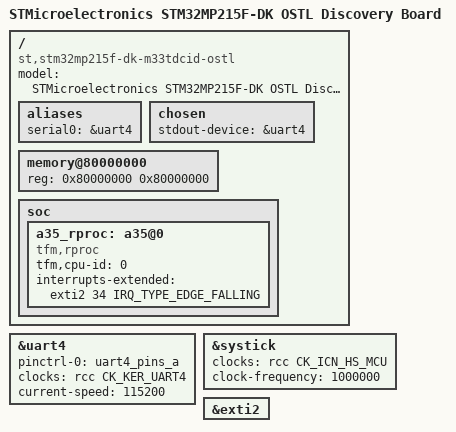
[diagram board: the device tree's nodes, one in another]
// SPDX-License-Identifier: (GPL-2.0-only OR BSD-3-Clause)
/*
 * Copyright (C) STMicroelectronics 2023 - All Rights Reserved
 */

/dts-v1/;

#include <dt-bindings/clock/stm32mp21-clksrc.h>
#include <dt-bindings/reset/st,stm32mp21-rcc.h>

#include "stm32mp215.dtsi"
#include "stm32mp21x-ns.dtsi"
#include "stm32mp215f-dk-cm33tdcid-ostl-resmem.dtsi"
#include "stm32mp215f-dk-cm33tdcid-ostl-ns-rcc.dtsi"
#include "stm32mp21-pinctrl.dtsi"
#include "stm32mp21xxan-pinctrl.dtsi"

/delete-node/ &a35_rproc;

/ {
	model = "STMicroelectronics STM32MP215F-DK OSTL Discovery Board";
	compatible = "st,stm32mp215f-dk-m33tdcid-ostl", "st,stm32mp215f-dk", "st,stm32mp215";

	aliases {
		serial0 = &uart4;
	};

	chosen {
		stdout-device = &uart4;
	};

	memory@80000000 {
		device_type = "memory";
		reg = <0x80000000 0x80000000>;
	};

	soc {
		a35_rproc: a35@0 {
			compatible = "tfm,rproc";
			#remoteproc-cells = <0>;
			tfm,cpu-id = <0>;
			interrupts-extended = <&exti2 34 IRQ_TYPE_EDGE_FALLING>;
			interrupt-names = "wdog";
		};
	};
};

&uart4 {
	pinctrl-names = "default";
	pinctrl-0 = <&uart4_pins_a>;
	clocks = <&rcc CK_KER_UART4>;
	current-speed = <115200>;
	status = "okay";
};

&systick {
	clocks = <&rcc CK_ICN_HS_MCU>;
	clock-frequency = <1000000>; /* tick at 1us */
	status = "okay";
};

&exti2 {
	status = "okay";
};
